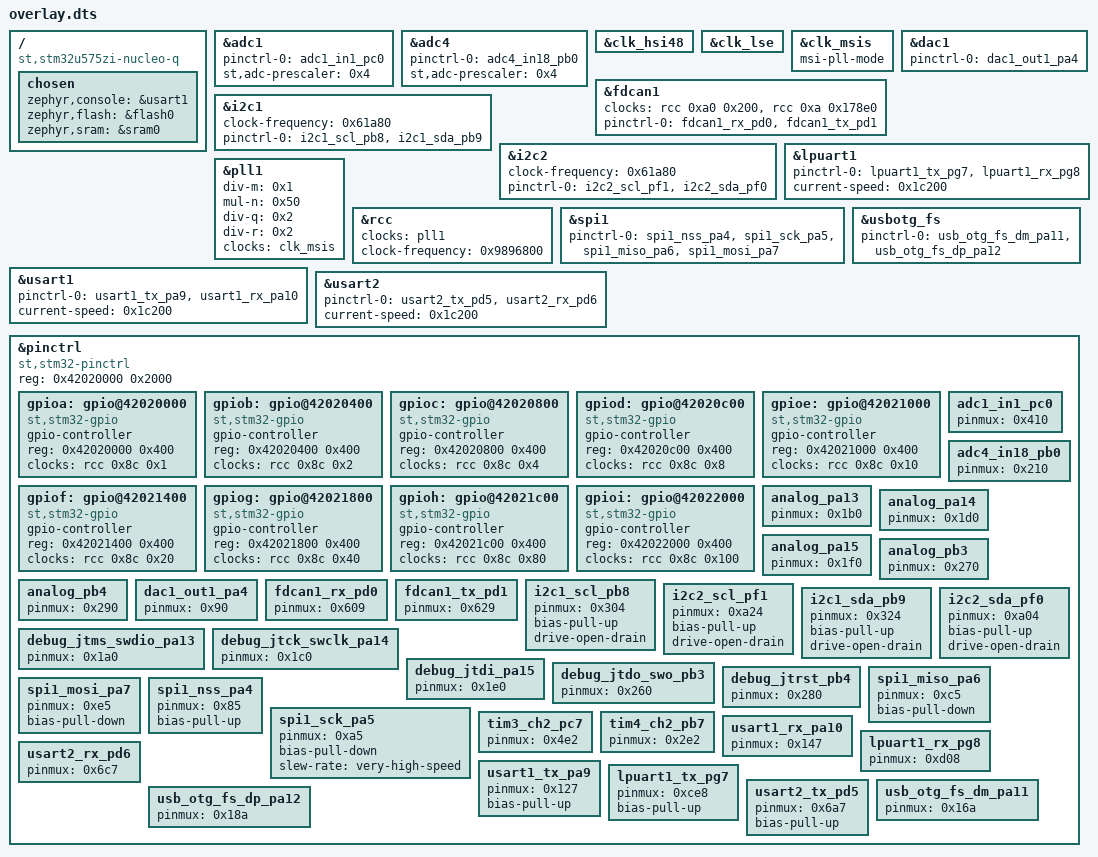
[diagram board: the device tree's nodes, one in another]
/ {
	compatible = "st,stm32u575zi-nucleo-q";
	chosen {
		zephyr,console = &usart1;
		zephyr,flash = &flash0;
		zephyr,sram = &sram0;
	};
};
&adc1{
	status = "okay";
	pinctrl-0 = < &adc1_in1_pc0 >;
	pinctrl-names = "default";
	st,adc-prescaler = < 0x4 >;
};
&adc4{
	status = "okay";
	pinctrl-0 = < &adc4_in18_pb0 >;
	pinctrl-names = "default";
	st,adc-prescaler = < 0x4 >;
};
&clk_hsi48{
	status = "okay";
};
&clk_lse{
	status = "okay";
};
&clk_msis{
	status = "okay";
	msi-pll-mode;
};
&dac1{
	status = "okay";
	pinctrl-0 = < &dac1_out1_pa4 >;
	pinctrl-names = "default";
};
&fdcan1{
	clocks = < &rcc 0xa0 0x200 >, < &rcc 0xa 0x178e0 >;
	status = "okay";
	pinctrl-0 = < &fdcan1_rx_pd0 &fdcan1_tx_pd1 >;
	pinctrl-names = "default";
};
&i2c1{
	clock-frequency = < 0x61a80 >;
	status = "okay";
	pinctrl-0 = < &i2c1_scl_pb8 &i2c1_sda_pb9 >;
	pinctrl-names = "default";
};
&i2c2{
	clock-frequency = < 0x61a80 >;
	status = "okay";
	pinctrl-0 = < &i2c2_scl_pf1 &i2c2_sda_pf0 >;
	pinctrl-names = "default";
};
&lpuart1{
	status = "okay";
	pinctrl-0 = < &lpuart1_tx_pg7 &lpuart1_rx_pg8 >;
	pinctrl-names = "default";
	current-speed = < 0x1c200 >;
};
&pll1{
	status = "okay";
	div-m = < 0x1 >;
	mul-n = < 0x50 >;
	div-q = < 0x2 >;
	div-r = < 0x2 >;
	clocks = < &clk_msis >;
};
&rcc{
	clocks = < &pll1 >;
	clock-frequency = < 0x9896800 >;
};
&spi1{
	status = "okay";
	pinctrl-0 = < &spi1_nss_pa4 &spi1_sck_pa5 &spi1_miso_pa6 &spi1_mosi_pa7 >;
	pinctrl-names = "default";
};
&usart1{
	status = "okay";
	pinctrl-0 = < &usart1_tx_pa9 &usart1_rx_pa10 >;
	pinctrl-names = "default";
	current-speed = < 0x1c200 >;
};
&usart2{
	status = "okay";
	pinctrl-0 = < &usart2_tx_pd5 &usart2_rx_pd6 >;
	pinctrl-names = "default";
	current-speed = < 0x1c200 >;
};
&usbotg_fs{
	status = "okay";
	pinctrl-0 = < &usb_otg_fs_dm_pa11 &usb_otg_fs_dp_pa12 >;
	pinctrl-names = "default";
};
&pinctrl{
	compatible = "st,stm32-pinctrl";
	#address-cells = < 0x1 >;
	#size-cells = < 0x1 >;
	reg = < 0x42020000 0x2000 >;
	gpioa: gpio@42020000 {
		compatible = "st,stm32-gpio";
		gpio-controller;
		#gpio-cells = < 0x2 >;
		reg = < 0x42020000 0x400 >;
		clocks = < &rcc 0x8c 0x1 >;
	};
	gpiob: gpio@42020400 {
		compatible = "st,stm32-gpio";
		gpio-controller;
		#gpio-cells = < 0x2 >;
		reg = < 0x42020400 0x400 >;
		clocks = < &rcc 0x8c 0x2 >;
	};
	gpioc: gpio@42020800 {
		compatible = "st,stm32-gpio";
		gpio-controller;
		#gpio-cells = < 0x2 >;
		reg = < 0x42020800 0x400 >;
		clocks = < &rcc 0x8c 0x4 >;
	};
	gpiod: gpio@42020c00 {
		compatible = "st,stm32-gpio";
		gpio-controller;
		#gpio-cells = < 0x2 >;
		reg = < 0x42020c00 0x400 >;
		clocks = < &rcc 0x8c 0x8 >;
	};
	gpioe: gpio@42021000 {
		compatible = "st,stm32-gpio";
		gpio-controller;
		#gpio-cells = < 0x2 >;
		reg = < 0x42021000 0x400 >;
		clocks = < &rcc 0x8c 0x10 >;
	};
	gpiof: gpio@42021400 {
		compatible = "st,stm32-gpio";
		gpio-controller;
		#gpio-cells = < 0x2 >;
		reg = < 0x42021400 0x400 >;
		clocks = < &rcc 0x8c 0x20 >;
	};
	gpiog: gpio@42021800 {
		compatible = "st,stm32-gpio";
		gpio-controller;
		#gpio-cells = < 0x2 >;
		reg = < 0x42021800 0x400 >;
		clocks = < &rcc 0x8c 0x40 >;
	};
	gpioh: gpio@42021c00 {
		compatible = "st,stm32-gpio";
		gpio-controller;
		#gpio-cells = < 0x2 >;
		reg = < 0x42021c00 0x400 >;
		clocks = < &rcc 0x8c 0x80 >;
	};
	gpioi: gpio@42022000 {
		compatible = "st,stm32-gpio";
		gpio-controller;
		#gpio-cells = < 0x2 >;
		reg = < 0x42022000 0x400 >;
		clocks = < &rcc 0x8c 0x100 >;
	};
	adc1_in1_pc0: adc1_in1_pc0 {
		pinmux = < 0x410 >;
	};
	adc4_in18_pb0: adc4_in18_pb0 {
		pinmux = < 0x210 >;
	};
	analog_pa13: analog_pa13 {
		pinmux = < 0x1b0 >;
	};
	analog_pa14: analog_pa14 {
		pinmux = < 0x1d0 >;
	};
	analog_pa15: analog_pa15 {
		pinmux = < 0x1f0 >;
	};
	analog_pb3: analog_pb3 {
		pinmux = < 0x270 >;
	};
	analog_pb4: analog_pb4 {
		pinmux = < 0x290 >;
	};
	dac1_out1_pa4: dac1_out1_pa4 {
		pinmux = < 0x90 >;
	};
	fdcan1_rx_pd0: fdcan1_rx_pd0 {
		pinmux = < 0x609 >;
	};
	fdcan1_tx_pd1: fdcan1_tx_pd1 {
		pinmux = < 0x629 >;
	};
	i2c1_scl_pb8: i2c1_scl_pb8 {
		pinmux = < 0x304 >;
		bias-pull-up;
		drive-open-drain;
	};
	i2c2_scl_pf1: i2c2_scl_pf1 {
		pinmux = < 0xa24 >;
		bias-pull-up;
		drive-open-drain;
	};
	i2c1_sda_pb9: i2c1_sda_pb9 {
		pinmux = < 0x324 >;
		bias-pull-up;
		drive-open-drain;
	};
	i2c2_sda_pf0: i2c2_sda_pf0 {
		pinmux = < 0xa04 >;
		bias-pull-up;
		drive-open-drain;
	};
	debug_jtms_swdio_pa13: debug_jtms_swdio_pa13 {
		pinmux = < 0x1a0 >;
	};
	debug_jtck_swclk_pa14: debug_jtck_swclk_pa14 {
		pinmux = < 0x1c0 >;
	};
	debug_jtdi_pa15: debug_jtdi_pa15 {
		pinmux = < 0x1e0 >;
	};
	debug_jtdo_swo_pb3: debug_jtdo_swo_pb3 {
		pinmux = < 0x260 >;
	};
	debug_jtrst_pb4: debug_jtrst_pb4 {
		pinmux = < 0x280 >;
	};
	spi1_miso_pa6: spi1_miso_pa6 {
		pinmux = < 0xc5 >;
		bias-pull-down;
	};
	spi1_mosi_pa7: spi1_mosi_pa7 {
		pinmux = < 0xe5 >;
		bias-pull-down;
	};
	spi1_nss_pa4: spi1_nss_pa4 {
		pinmux = < 0x85 >;
		bias-pull-up;
	};
	spi1_sck_pa5: spi1_sck_pa5 {
		pinmux = < 0xa5 >;
		bias-pull-down;
		slew-rate = "very-high-speed";
	};
	tim3_ch2_pc7: tim3_ch2_pc7 {
		pinmux = < 0x4e2 >;
	};
	tim4_ch2_pb7: tim4_ch2_pb7 {
		pinmux = < 0x2e2 >;
	};
	usart1_rx_pa10: usart1_rx_pa10 {
		pinmux = < 0x147 >;
	};
	lpuart1_rx_pg8: lpuart1_rx_pg8 {
		pinmux = < 0xd08 >;
	};
	usart2_rx_pd6: usart2_rx_pd6 {
		pinmux = < 0x6c7 >;
	};
	usart1_tx_pa9: usart1_tx_pa9 {
		pinmux = < 0x127 >;
		bias-pull-up;
	};
	lpuart1_tx_pg7: lpuart1_tx_pg7 {
		pinmux = < 0xce8 >;
		bias-pull-up;
	};
	usart2_tx_pd5: usart2_tx_pd5 {
		pinmux = < 0x6a7 >;
		bias-pull-up;
	};
	usb_otg_fs_dm_pa11: usb_otg_fs_dm_pa11 {
		pinmux = < 0x16a >;
	};
	usb_otg_fs_dp_pa12: usb_otg_fs_dp_pa12 {
		pinmux = < 0x18a >;
	};
};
